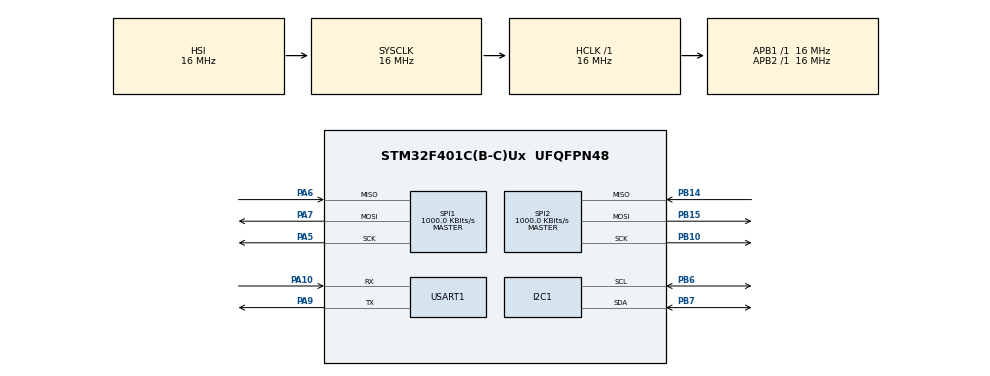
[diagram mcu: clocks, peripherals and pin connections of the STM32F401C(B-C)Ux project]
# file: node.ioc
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FREERTOS.Tasks01=defaultTask,24,128,StartDefaultTask,Default,NULL,Dynamic,NULL,NULL
FREERTOS.configTOTAL_HEAP_SIZE=4096
FREERTOS.configUSE_NEWLIB_REENTRANT=1
Mcu.Family=STM32F4
Mcu.Name=STM32F401C(B-C)Ux
Mcu.Package=UFQFPN48
NVIC.PriorityGroup=NVIC_PRIORITYGROUP_4
NVIC.RTC_WKUP_IRQn=true\:5\:0\:false\:false\:true\:true\:true\:true\:true
NVIC.TIM5_IRQn=true\:15\:0\:false\:false\:true\:false\:false\:true\:true
NVIC.TimeBase=TIM5_IRQn
NVIC.TimeBaseIP=TIM5
PA10.Mode=Asynchronous
PA10.Signal=USART1_RX
PA5.Mode=Full_Duplex_Master
PA5.Signal=SPI1_SCK
PA6.Mode=Full_Duplex_Master
PA6.Signal=SPI1_MISO
PA7.Mode=Full_Duplex_Master
PA7.Signal=SPI1_MOSI
PA9.Mode=Asynchronous
PA9.Signal=USART1_TX
PB10.Mode=Full_Duplex_Master
PB10.Signal=SPI2_SCK
PB14.Mode=Full_Duplex_Master
PB14.Signal=SPI2_MISO
PB15.Mode=Full_Duplex_Master
PB15.Signal=SPI2_MOSI
PB6.Mode=I2C
PB6.Signal=I2C1_SCL
PB7.Mode=I2C
PB7.Signal=I2C1_SDA
ProjectManager.HeapSize=0x200
ProjectManager.StackSize=0x400
ProjectManager.TargetToolchain=STM32CubeIDE
RCC.AHBFreq_Value=16000000
RCC.APB1Freq_Value=16000000
RCC.APB2Freq_Value=16000000
RCC.CortexFreq_Value=16000000
RCC.HSE_VALUE=25000000
RCC.HSI_VALUE=16000000
RCC.LSE_VALUE=32768
RCC.SYSCLKFreq_VALUE=16000000
RCC.VCOOutputFreq_Value=192000000
SPI1.BaudRatePrescaler=SPI_BAUDRATEPRESCALER_16
SPI1.CalculateBaudRate=1000.0 KBits/s
SPI1.Direction=SPI_DIRECTION_2LINES
SPI1.Mode=SPI_MODE_MASTER
SPI1.VirtualType=VM_MASTER
SPI2.BaudRatePrescaler=SPI_BAUDRATEPRESCALER_16
SPI2.CalculateBaudRate=1000.0 KBits/s
SPI2.Direction=SPI_DIRECTION_2LINES
SPI2.Mode=SPI_MODE_MASTER
SPI2.VirtualType=VM_MASTER
USART1.VirtualMode=VM_ASYNC
VP_FREERTOS_VS_CMSIS_V2.Mode=CMSIS_V2
VP_RTC_VS_RTC_Activate.Mode=RTC_Enabled
VP_RTC_VS_RTC_Calendar.Mode=RTC_Calendar
VP_RTC_VS_RTC_WakeUp_intern.Mode=WakeUp
VP_SYS_VS_tim5.Mode=TIM5
board=custom

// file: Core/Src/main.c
/* USER CODE BEGIN Header */
/**
  ******************************************************************************
  * @file           : main.c
  * @brief          : Main program body
  ******************************************************************************
  * @attention
  *
  * Copyright (c) 2026 STMicroelectronics.
  * All rights reserved.
  *
  * This software is licensed under terms that can be found in the LICENSE file
  * in the root directory of this software component.
  * If no LICENSE file comes with this software, it is provided AS-IS.
  *
  ******************************************************************************
  */
/* USER CODE END Header */
#include "main.h"
#include "cmsis_os.h"

/* USER CODE BEGIN Includes */
#include "node.h"
#include <string.h>
#include <stdio.h>

/* USER CODE END Includes */

I2C_HandleTypeDef hi2c1;

RTC_HandleTypeDef hrtc;

SPI_HandleTypeDef hspi1;
SPI_HandleTypeDef hspi2;

UART_HandleTypeDef huart1;

/* Definitions for defaultTask */
osThreadId_t defaultTaskHandle;
const osThreadAttr_t defaultTask_attributes = {
  .name = "defaultTask",
  .stack_size = 128 * 4,
  .priority = (osPriority_t) osPriorityNormal,
};

void SystemClock_Config(void);
static void MX_GPIO_Init(void);
static void MX_SPI2_Init(void);
static void MX_USART1_UART_Init(void);
static void MX_SPI1_Init(void);
static void MX_RTC_Init(void);
static void MX_I2C1_Init(void);
void StartDefaultTask(void *argument);

int main(void)
{

  /* MCU Configuration--------------------------------------------------------*/

  /* Reset of all peripherals, Initializes the Flash interface and the Systick. */
  HAL_Init();

  /* Configure the system clock */
  SystemClock_Config();

  /* Initialize all configured peripherals */
  MX_GPIO_Init();
  MX_SPI2_Init();
  MX_USART1_UART_Init();
  MX_SPI1_Init();
  MX_RTC_Init();
  MX_I2C1_Init();

  /* Init scheduler */
  osKernelInitialize();

  /* Create the thread(s) */
  /* creation of defaultTask */
  defaultTaskHandle = osThreadNew(StartDefaultTask, NULL, &defaultTask_attributes);

  /* USER CODE BEGIN RTOS_THREADS */
  /* add threads, ... */
  node_start();
  /* USER CODE END RTOS_THREADS */

  /* Start scheduler */
  osKernelStart();

  /* We should never get here as control is now taken by the scheduler */

  /* Infinite loop */
  while (1)
  {

  }
}

void SystemClock_Config(void)
{
  RCC_OscInitTypeDef RCC_OscInitStruct = {0};
  RCC_ClkInitTypeDef RCC_ClkInitStruct = {0};

  /** Configure the main internal regulator output voltage
  */
  __HAL_RCC_PWR_CLK_ENABLE();
  __HAL_PWR_VOLTAGESCALING_CONFIG(PWR_REGULATOR_VOLTAGE_SCALE2);

  /** Initializes the RCC Oscillators according to the specified parameters
  * in the RCC_OscInitTypeDef structure.
  */
  RCC_OscInitStruct.OscillatorType = RCC_OSCILLATORTYPE_HSI|RCC_OSCILLATORTYPE_LSI;
  RCC_OscInitStruct.HSIState = RCC_HSI_ON;
  RCC_OscInitStruct.HSICalibrationValue = RCC_HSICALIBRATION_DEFAULT;
  RCC_OscInitStruct.LSIState = RCC_LSI_ON;
  RCC_OscInitStruct.PLL.PLLState = RCC_PLL_NONE;
  if (HAL_RCC_OscConfig(&RCC_OscInitStruct) != HAL_OK)
  {
    Error_Handler();
  }

  /** Initializes the CPU, AHB and APB buses clocks
  */
  RCC_ClkInitStruct.ClockType = RCC_CLOCKTYPE_HCLK|RCC_CLOCKTYPE_SYSCLK
                              |RCC_CLOCKTYPE_PCLK1|RCC_CLOCKTYPE_PCLK2;
  RCC_ClkInitStruct.SYSCLKSource = RCC_SYSCLKSOURCE_HSI;
  RCC_ClkInitStruct.AHBCLKDivider = RCC_SYSCLK_DIV1;
  RCC_ClkInitStruct.APB1CLKDivider = RCC_HCLK_DIV1;
  RCC_ClkInitStruct.APB2CLKDivider = RCC_HCLK_DIV1;

  if (HAL_RCC_ClockConfig(&RCC_ClkInitStruct, FLASH_LATENCY_0) != HAL_OK)
  {
    Error_Handler();
  }
}

static void MX_I2C1_Init(void)
{

  hi2c1.Instance = I2C1;
  hi2c1.Init.ClockSpeed = 100000;
  hi2c1.Init.DutyCycle = I2C_DUTYCYCLE_2;
  hi2c1.Init.OwnAddress1 = 0;
  hi2c1.Init.AddressingMode = I2C_ADDRESSINGMODE_7BIT;
  hi2c1.Init.DualAddressMode = I2C_DUALADDRESS_DISABLE;
  hi2c1.Init.OwnAddress2 = 0;
  hi2c1.Init.GeneralCallMode = I2C_GENERALCALL_DISABLE;
  hi2c1.Init.NoStretchMode = I2C_NOSTRETCH_DISABLE;
  if (HAL_I2C_Init(&hi2c1) != HAL_OK)
  {
    Error_Handler();
  }

}

static void MX_RTC_Init(void)
{

  RTC_TimeTypeDef sTime = {0};
  RTC_DateTypeDef sDate = {0};

  /** Initialize RTC Only
  */
  hrtc.Instance = RTC;
  hrtc.Init.HourFormat = RTC_HOURFORMAT_24;
  hrtc.Init.AsynchPrediv = 127;
  hrtc.Init.SynchPrediv = 255;
  hrtc.Init.OutPut = RTC_OUTPUT_DISABLE;
  hrtc.Init.OutPutPolarity = RTC_OUTPUT_POLARITY_HIGH;
  hrtc.Init.OutPutType = RTC_OUTPUT_TYPE_OPENDRAIN;
  if (HAL_RTC_Init(&hrtc) != HAL_OK)
  {
    Error_Handler();
  }

  /** Initialize RTC and set the Time and Date
  */
  sTime.Hours = 0x0;
  sTime.Minutes = 0x0;
  sTime.Seconds = 0x0;
  sTime.DayLightSaving = RTC_DAYLIGHTSAVING_NONE;
  sTime.StoreOperation = RTC_STOREOPERATION_RESET;
  if (HAL_RTC_SetTime(&hrtc, &sTime, RTC_FORMAT_BCD) != HAL_OK)
  {
    Error_Handler();
  }
  sDate.WeekDay = RTC_WEEKDAY_MONDAY;
  sDate.Month = RTC_MONTH_JANUARY;
  sDate.Date = 0x1;
  sDate.Year = 0x0;

  if (HAL_RTC_SetDate(&hrtc, &sDate, RTC_FORMAT_BCD) != HAL_OK)
  {
    Error_Handler();
  }

  /** Enable the WakeUp
  */
  if (HAL_RTCEx_SetWakeUpTimer_IT(&hrtc, 0, RTC_WAKEUPCLOCK_RTCCLK_DIV16) != HAL_OK)
  {
    Error_Handler();
  }
  /* USER CODE BEGIN RTC_Init 2 */
  /* Wake-up timer is armed only in node_deep_sleep(). */
  HAL_RTCEx_DeactivateWakeUpTimer(&hrtc);
  /* USER CODE END RTC_Init 2 */

}

static void MX_SPI1_Init(void)
{

  /* SPI1 parameter configuration*/
  hspi1.Instance = SPI1;
  hspi1.Init.Mode = SPI_MODE_MASTER;
  hspi1.Init.Direction = SPI_DIRECTION_2LINES;
  hspi1.Init.DataSize = SPI_DATASIZE_8BIT;
  hspi1.Init.CLKPolarity = SPI_POLARITY_LOW;
  hspi1.Init.CLKPhase = SPI_PHASE_1EDGE;
  hspi1.Init.NSS = SPI_NSS_SOFT;
  hspi1.Init.BaudRatePrescaler = SPI_BAUDRATEPRESCALER_16;
  hspi1.Init.FirstBit = SPI_FIRSTBIT_MSB;
  hspi1.Init.TIMode = SPI_TIMODE_DISABLE;
  hspi1.Init.CRCCalculation = SPI_CRCCALCULATION_DISABLE;
  hspi1.Init.CRCPolynomial = 10;
  if (HAL_SPI_Init(&hspi1) != HAL_OK)
  {
    Error_Handler();
  }

}

static void MX_SPI2_Init(void)
{

  /* SPI2 parameter configuration*/
  hspi2.Instance = SPI2;
  hspi2.Init.Mode = SPI_MODE_MASTER;
  hspi2.Init.Direction = SPI_DIRECTION_2LINES;
  hspi2.Init.DataSize = SPI_DATASIZE_8BIT;
  hspi2.Init.CLKPolarity = SPI_POLARITY_LOW;
  hspi2.Init.CLKPhase = SPI_PHASE_1EDGE;
  hspi2.Init.NSS = SPI_NSS_SOFT;
  hspi2.Init.BaudRatePrescaler = SPI_BAUDRATEPRESCALER_16;
  hspi2.Init.FirstBit = SPI_FIRSTBIT_MSB;
  hspi2.Init.TIMode = SPI_TIMODE_DISABLE;
  hspi2.Init.CRCCalculation = SPI_CRCCALCULATION_DISABLE;
  hspi2.Init.CRCPolynomial = 10;
  if (HAL_SPI_Init(&hspi2) != HAL_OK)
  {
    Error_Handler();
  }

}

static void MX_USART1_UART_Init(void)
{

  huart1.Instance = USART1;
  huart1.Init.BaudRate = 115200;
  huart1.Init.WordLength = UART_WORDLENGTH_8B;
  huart1.Init.StopBits = UART_STOPBITS_1;
  huart1.Init.Parity = UART_PARITY_NONE;
  huart1.Init.Mode = UART_MODE_TX_RX;
  huart1.Init.HwFlowCtl = UART_HWCONTROL_NONE;
  huart1.Init.OverSampling = UART_OVERSAMPLING_16;
  if (HAL_UART_Init(&huart1) != HAL_OK)
  {
    Error_Handler();
  }

}

static void MX_GPIO_Init(void)
{

  /* GPIO Ports Clock Enable */
  __HAL_RCC_GPIOA_CLK_ENABLE();
  __HAL_RCC_GPIOB_CLK_ENABLE();

}

void StartDefaultTask(void *argument)
{
  /* USER CODE BEGIN 5 */
  osThreadExit();
  /* USER CODE END 5 */
}

void HAL_TIM_PeriodElapsedCallback(TIM_HandleTypeDef *htim)
{
  if (htim->Instance == TIM5)
  {
    HAL_IncTick();
  }
}

void Error_Handler(void)
{
  __disable_irq();
  while (1)
  {
  }
}
